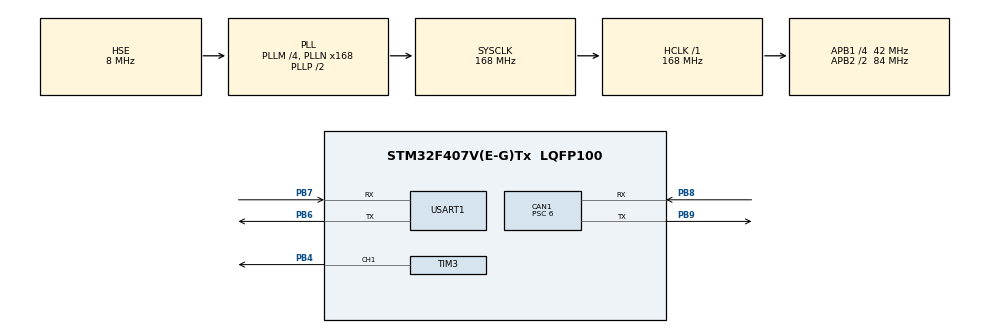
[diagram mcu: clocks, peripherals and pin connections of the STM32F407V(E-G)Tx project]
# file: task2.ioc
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# ============================================================================
# 任务一 CubeMX 配置（立创·梁山派·天空星 STM32F407VGT6）
#
#  ⚠️ 重要：本工程的外设初始化代码已经手写完成（can.c / dma.c / tim.c），
#     效果与 CubeMX 生成完全等价，**直接用 Keil 打开编译下载即可**。
#     这个 .ioc 是"配置记录 / 以后改配置的入口"。
#     如果你在 CubeMX 里点 GENERATE CODE，请先阅读
#     《任务一接线与验收说明.md》第 6 节「用 CubeMX 重新生成的注意事项」，
#     否则会出现中断函数重复定义。
# ============================================================================
CAN1.BS1=CAN_BS1_9TQ
CAN1.BS2=CAN_BS2_4TQ
CAN1.CalculateBaudRate=500000
CAN1.Mode=CAN_MODE_NORMAL
CAN1.Prescaler=6
CAN1.SJW=CAN_SJW_1TQ
Dma.Request0=USART1_RX
Dma.Request1=USART1_TX
Dma.USART1_RX.0.Direction=DMA_PERIPH_TO_MEMORY
Dma.USART1_RX.0.FIFOMode=DMA_FIFOMODE_DISABLE
Dma.USART1_RX.0.Instance=DMA2_Stream2
Dma.USART1_RX.0.MemDataAlignment=DMA_MDATAALIGN_BYTE
Dma.USART1_RX.0.MemInc=DMA_MINC_ENABLE
Dma.USART1_RX.0.Mode=DMA_CIRCULAR
Dma.USART1_RX.0.PeriphDataAlignment=DMA_PDATAALIGN_BYTE
Dma.USART1_RX.0.PeriphInc=DMA_PINC_DISABLE
Dma.USART1_RX.0.Priority=DMA_PRIORITY_LOW
Dma.USART1_TX.1.Direction=DMA_MEMORY_TO_PERIPH
Dma.USART1_TX.1.FIFOMode=DMA_FIFOMODE_DISABLE
Dma.USART1_TX.1.Instance=DMA2_Stream7
Dma.USART1_TX.1.MemDataAlignment=DMA_MDATAALIGN_BYTE
Dma.USART1_TX.1.MemInc=DMA_MINC_ENABLE
Dma.USART1_TX.1.Mode=DMA_NORMAL
Dma.USART1_TX.1.PeriphDataAlignment=DMA_PDATAALIGN_BYTE
Dma.USART1_TX.1.PeriphInc=DMA_PINC_DISABLE
Dma.USART1_TX.1.Priority=DMA_PRIORITY_LOW
FREERTOS.Tasks01=defaultTask,24,128,StartDefaultTask,Default,NULL,Dynamic,NULL,NULL
Mcu.Family=STM32F4
Mcu.Name=STM32F407V(E-G)Tx
Mcu.Package=LQFP100
NVIC.CAN1_RX0_IRQn=true\:5\:0\:false\:false\:true\:true\:true\:true
NVIC.DMA2_Stream7_IRQn=true\:5\:0\:false\:false\:true\:true\:true\:true
NVIC.PriorityGroup=NVIC_PRIORITYGROUP_4
NVIC.TIM1_UP_TIM10_IRQn=true\:0\:0\:false\:false\:true\:false\:false\:true
NVIC.TIM7_IRQn=true\:6\:0\:false\:false\:true\:true\:false\:true
NVIC.TimeBase=TIM1_UP_TIM10_IRQn
NVIC.TimeBaseIP=TIM1
NVIC.USART1_IRQn=true\:5\:0\:false\:false\:true\:true\:true\:true
PA13.Mode=Serial_Wire
PA13.Signal=SYS_JTMS-SWDIO
PA14.Mode=Serial_Wire
PA14.Signal=SYS_JTCK-SWCLK
PB4.Signal=S_TIM3_CH1
PB6.Mode=Asynchronous
PB6.Signal=USART1_TX
PB7.Mode=Asynchronous
PB7.Signal=USART1_RX
PB8.Mode=Master
PB8.Signal=CAN1_RX
PB9.Mode=Master
PB9.Signal=CAN1_TX
PH0-OSC_IN.Mode=HSE-External-Oscillator
PH0-OSC_IN.Signal=RCC_OSC_IN
PH1-OSC_OUT.Mode=HSE-External-Oscillator
PH1-OSC_OUT.Signal=RCC_OSC_OUT
ProjectManager.HeapSize=0x200
ProjectManager.StackSize=0x400
ProjectManager.TargetToolchain=MDK-ARM V5.27
RCC.48MHZClocksFreq_Value=84000000
RCC.AHBFreq_Value=168000000
RCC.APB1CLKDivider=RCC_HCLK_DIV4
RCC.APB1Freq_Value=42000000
RCC.APB1TimFreq_Value=84000000
RCC.APB2CLKDivider=RCC_HCLK_DIV2
RCC.APB2Freq_Value=84000000
RCC.APB2TimFreq_Value=168000000
RCC.CortexFreq_Value=168000000
RCC.HCLKFreq_Value=168000000
RCC.HSE_VALUE=8000000
RCC.HSI_VALUE=16000000
RCC.LSE_VALUE=32768
RCC.PLLM=4
RCC.PLLN=168
RCC.PLLSourceVirtual=RCC_PLLSOURCE_HSE
RCC.SYSCLKFreq_VALUE=168000000
RCC.SYSCLKSource=RCC_SYSCLKSOURCE_PLLCLK
RCC.VCOOutputFreq_Value=336000000
SH.S_TIM3_CH1.0=TIM3_CH1,PWM Generation1 CH1
TIM3.AutoReloadPreload=TIM_AUTORELOAD_PRELOAD_ENABLE
TIM3.Channel-PWM\ Generation1\ CH1=TIM_CHANNEL_1
TIM3.OCMode_PWM-PWM\ Generation1\ CH1=TIM_OCMODE_PWM1
TIM3.Period=999
TIM3.Prescaler=83
TIM7.AutoReloadPreload=TIM_AUTORELOAD_PRELOAD_ENABLE
TIM7.Period=999
TIM7.Prescaler=83
USART1.VirtualMode=VM_ASYNC
VP_FREERTOS_VS_CMSIS_V2.Mode=CMSIS_V2
VP_SYS_VS_tim1.Mode=TIM1
VP_TIM3_VS_ClockSourceINT.Mode=Internal
board=custom

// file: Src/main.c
/* USER CODE BEGIN Header */
/**
  ******************************************************************************
  * @file           : main.c
  * @brief          : 任务一 —— CAN 接收 + 呼吸灯 + 串口 DMA 回传
  *
  *  数据流：
  *    CAN 中断 ──(队列6)──> Task_CanRx ──(任务通知)──> Task_Breath ──> 呼吸周期
  *    USART 空闲中断 ──(队列3)──> Task_UartEcho ──(DMA 发送)──> VOFA
  *    呼吸波形 = TIM7(1kHz 中断) + TIM3(PWM)，不依赖任何任务
  ******************************************************************************
  * @attention
  *
  * <h2><center>&copy; Copyright (c) 2026 STMicroelectronics.
  * All rights reserved.</center></h2>
  *
  ******************************************************************************
  */
/* USER CODE END Header */
#include "main.h"
#include "cmsis_os.h"
#include "can.h"
#include "dma.h"
#include "tim.h"
#include "usart.h"
#include "gpio.h"

/* USER CODE BEGIN Includes */
#include <stdio.h>
#include "board_config.h"
#include "can_bus.h"
#include "uart_vofa.h"
#include "breath_led.h"
/* USER CODE END Includes */

void SystemClock_Config(void);
void MX_FREERTOS_Init(void);

int main(void)
{

  /* MCU Configuration--------------------------------------------------------*/

  /* Reset of all peripherals, Initializes the Flash interface and the Systick. */
  HAL_Init();

  /* Configure the system clock */
  SystemClock_Config();

  /* Initialize all configured peripherals */
  MX_GPIO_Init();
  MX_DMA_Init();          /* 必须先于 MX_USART1_UART_Init（DMA 句柄要挂到 huart） */
  MX_TIM3_Init();         /* 呼吸灯 PWM：PB4 */
  MX_TIM7_Init();         /* 呼吸节拍 1 kHz */
  MX_CAN1_Init();         /* CAN1：PB8/PB9，500 kbps */
  MX_USART1_UART_Init();  /* VOFA 串口：PB6/PB7，115200 */
  /* USER CODE BEGIN 2 */
  printf("Task2 start: task1 features + MPU6050 (soft IIC PB0/PB1) + 5ms vTaskDelayUntil\r\n");
  printf("VOFA protocol: JustFloat | raw 6ch + DMP euler 3ch (if enabled)\r\n");
  /* USER CODE END 2 */

  /* Init scheduler */
  osKernelInitialize();  /* Call init function for freertos objects (in freertos.c) */
  MX_FREERTOS_Init();    /* 三个任务在 freertos.c 的 USER CODE RTOS_THREADS 区创建 */
  /* Start scheduler */
  osKernelStart();

  /* We should never get here as control is now taken by the scheduler */
  /* Infinite loop */
  /* USER CODE BEGIN WHILE */
  /* osKernelStart() 之后调度器接管 CPU，永远不会执行到这里 */
  /* USER CODE END WHILE */

}

void SystemClock_Config(void)
{
  RCC_OscInitTypeDef RCC_OscInitStruct = {0};
  RCC_ClkInitTypeDef RCC_ClkInitStruct = {0};

  /** Configure the main internal regulator output voltage
  */
  __HAL_RCC_PWR_CLK_ENABLE();
  __HAL_PWR_VOLTAGESCALING_CONFIG(PWR_REGULATOR_VOLTAGE_SCALE1);
  /** Initializes the RCC Oscillators according to the specified parameters
  * in the RCC_OscInitTypeDef structure.
  */
  RCC_OscInitStruct.OscillatorType = RCC_OSCILLATORTYPE_HSE;
  RCC_OscInitStruct.HSEState = RCC_HSE_ON;
  RCC_OscInitStruct.PLL.PLLState = RCC_PLL_ON;
  RCC_OscInitStruct.PLL.PLLSource = RCC_PLLSOURCE_HSE;
  RCC_OscInitStruct.PLL.PLLM = 4;
  RCC_OscInitStruct.PLL.PLLN = 168;
  RCC_OscInitStruct.PLL.PLLP = RCC_PLLP_DIV2;
  RCC_OscInitStruct.PLL.PLLQ = 4;
  if (HAL_RCC_OscConfig(&RCC_OscInitStruct) != HAL_OK)
  {
    Error_Handler();
  }
  /** Initializes the CPU, AHB and APB buses clocks
  */
  RCC_ClkInitStruct.ClockType = RCC_CLOCKTYPE_HCLK|RCC_CLOCKTYPE_SYSCLK
                              |RCC_CLOCKTYPE_PCLK1|RCC_CLOCKTYPE_PCLK2;
  RCC_ClkInitStruct.SYSCLKSource = RCC_SYSCLKSOURCE_PLLCLK;
  RCC_ClkInitStruct.AHBCLKDivider = RCC_SYSCLK_DIV1;
  RCC_ClkInitStruct.APB1CLKDivider = RCC_HCLK_DIV4;
  RCC_ClkInitStruct.APB2CLKDivider = RCC_HCLK_DIV2;

  if (HAL_RCC_ClockConfig(&RCC_ClkInitStruct, FLASH_LATENCY_5) != HAL_OK)
  {
    Error_Handler();
  }
}

/* USER CODE BEGIN 4 */

/**
  * @brief  CAN 接收中断回调：只把报文打包进队列（长度 6），解析交给任务
  */
void HAL_CAN_RxFifo0MsgPendingCallback(CAN_HandleTypeDef *hcan)
{
  CAN_RxFifo0Callback(hcan);
}

/* USER CODE END 4 */

 /**
  * @brief  Period elapsed callback in non blocking mode
  * @note   This function is called  when TIM1 interrupt took place, inside
  * HAL_TIM_IRQHandler(). It makes a direct call to HAL_IncTick() to increment
  * a global variable "uwTick" used as application time base.
  * @param  htim : TIM handle
  * @retval None
  */
void HAL_TIM_PeriodElapsedCallback(TIM_HandleTypeDef *htim)
{
  if (htim->Instance == TIM1) {
    HAL_IncTick();
  }
  /* USER CODE BEGIN Callback 1 */
  else if (htim->Instance == TIM7) {
    BreathLED_TickISR(htim);      /* 1 kHz：更新呼吸灯占空比（不依赖任务） */
  }
  /* USER CODE END Callback 1 */
}

void Error_Handler(void)
{
  __disable_irq();
  while (1)
  {
  }
}

/************************ (C) COPYRIGHT STMicroelectronics *****END OF FILE****/
